# STM32H503xx register map
File version: 1.0
Registers are 32-bit, read-write, reset 0x0 unless marked. A register's access mark holds for its fields unless they carry their own. Offsets are from the block's base; [hi:lo] are bit positions; {n}, {i} and the like mark numbered series; 'fields as' and 'values as' point back to an identical list.

## USB_DRD_PMA_BUFF — Universal Serial Bus PacketMemoryArea Buffer Descriptor Table
Base 0x40016400
0x00 TXBD — Transmission buffer address
0x04 RXBD — Reception buffer address

## CRC — CRC calculation unit
Base 0x40023000
0x00 DR — CRC Data register
  [31:0] DR — Data register bits
0x04 IDR — CRC Independent data register
  [31:0] IDR — General-purpose 32-bits data register bits
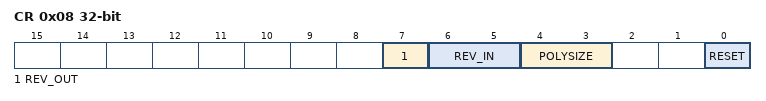
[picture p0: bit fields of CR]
0x08 CR — CRC Control register
  [7] REV_OUT — REV_OUT Reverse Output Data bits
    0=NONE (Output Data bit order not affected); 1=BIT (Output Data bit reversal done by bit)
  [6:5] REV_IN — REV_IN Reverse Input Data bits
    0=NONE (Input Data bit order not affected); 1=BYTE (Definition for compatibility with legacy code); 2=HALFWORD (Definition for compatibility with legacy code); 3=WORD (Definition for compatibility with legacy code)
  [4:3] POLYSIZE — Polynomial size bits
    0=POLYLENGTH_32B (32 bits Polynomial size); 1=POLYLENGTH_16B (16 bits Polynomial size); 2=POLYLENGTH_8B (8 bits Polynomial size); 3=POLYLENGTH_7B (7 bits Polynomial size)
  [0] RESET — RESET the CRC computation unit bit
0x10 INIT — Initial CRC value register
  [31:0] INIT — Initial CRC value bits
0x14 POL — CRC polynomial register
  [31:0] POL — Coefficients of the polynomial

## RAMCFG
Base 0x40026000
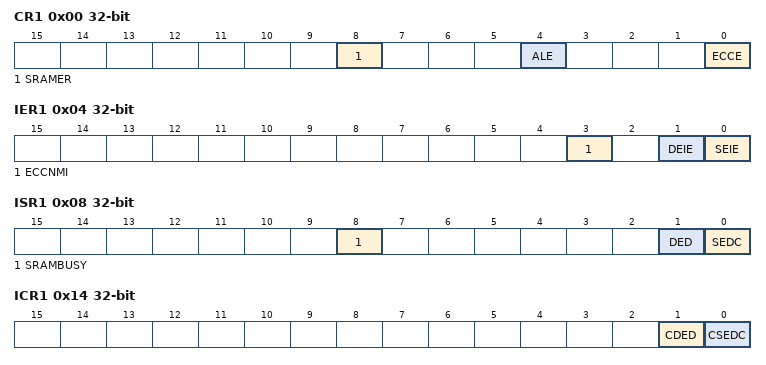
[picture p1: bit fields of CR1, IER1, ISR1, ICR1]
0x00 CR1 — Control Register
  [8] SRAMER — Start Erase
  [4] ALE — Address Latching Enable
  [0] ECCE — ECC Enable
0x04 IER1 — Interrupt Enable Register
  [3] ECCNMI — NMI redirection interrupt
  [1] DEIE — Double Error Interrupt Enable
  [0] SEIE — Single Error Interrupt Enable
0x08 ISR1 — Interrupt Status Register
  [8] SRAMBUSY — SRAM busy flag
  [1] DED — Double Error Detected flag
  [0] SEDC — Single Error Detected and Corrected flag
0x0C SEAR1 — ECC Single Error Address Register
  [31:0] ESEA — ECC Single Error Address
0x10 DEAR1 — ECC Double Error Address Register
  [31:0] EDEA — ECC Double Error Address
0x14 ICR1 — Interrupt Clear Register
  [1] CDED — Clear ECC Double Error Detected Flag
  [0] CSEDC — Clear ECC Single Error Detected and Corrected Flag
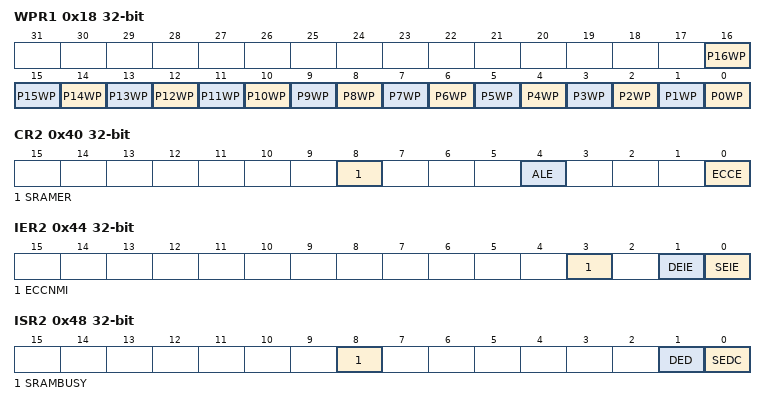
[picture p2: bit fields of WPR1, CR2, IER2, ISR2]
0x18 WPR1 — SRAM Write Protection Register 1
  [n] P{n}WP (n=0..16) — Write Protection Page {n:02}
0x1C WPR21 — SRAM Write Protection Register 2
0x24 ECCKEY1 — SRAM ECC Key Register
0x28 ERKEYR1 — SRAM Erase Key Register
  [7:0] ERASEKEY — Erase Write Protection Key
0x40 CR2 — Control Register
  fields as CR1
0x44 IER2 — Interrupt Enable Register
  fields as IER1
0x48 ISR2 — Interrupt Status Register
  fields as ISR1
0x4C SEAR2 — ECC Single Error Address Register
  [31:0] ESEA — ECC Single Error Address
0x50 DEAR2 — ECC Double Error Address Register
  [31:0] EDEA — ECC Double Error Address
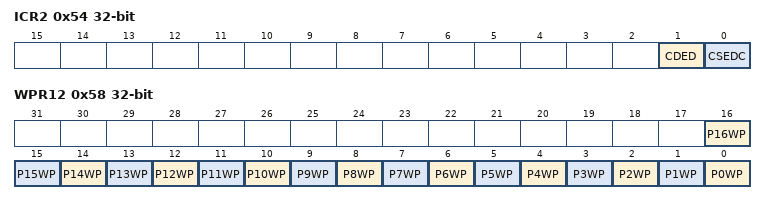
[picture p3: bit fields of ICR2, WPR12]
0x54 ICR2 — Interrupt Clear Register
  fields as ICR1
0x58 WPR12 — SRAM Write Protection Register 1
  [n] P{n}WP (n=0..16) — Write Protection Page {n:02}
0x5C WPR2 — SRAM Write Protection Register 2
0x64 ECCKEY2 — SRAM ECC Key Register
0x68 ERKEYR2 — SRAM Erase Key Register
  [7:0] ERASEKEY — Erase Write Protection Key

## RAMCFG_BKPRAM — SRAMs configuration controller
Base 0x40026100
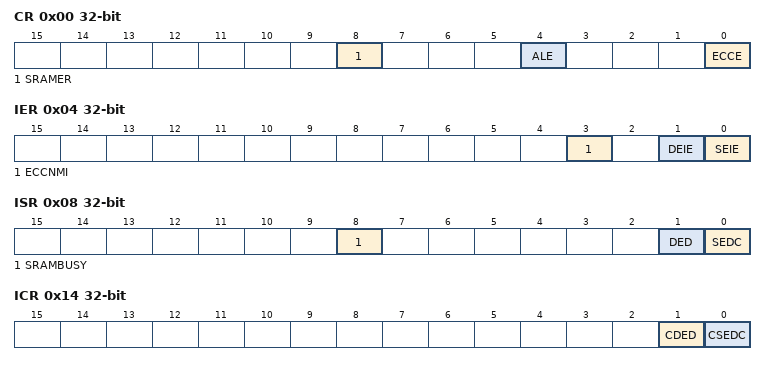
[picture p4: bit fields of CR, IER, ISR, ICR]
0x00 CR — Control Register
  [8] SRAMER — Start Erase
  [4] ALE — Address Latching Enable
  [0] ECCE — ECC Enable
0x04 IER — Interrupt Enable Register
  [3] ECCNMI — NMI redirection interrupt
  [1] DEIE — Double Error Interrupt Enable
  [0] SEIE — Single Error Interrupt Enable
0x08 ISR — Interrupt Status Register
  [8] SRAMBUSY — SRAM busy flag
  [1] DED — Double Error Detected flag
  [0] SEDC — Single Error Detected and Corrected flag
0x0C SEAR — ECC Single Error Address Register
  [31:0] ESEA — ECC Single Error Address
0x10 DEAR — ECC Double Error Address Register
  [31:0] EDEA — ECC Double Error Address
0x14 ICR — Interrupt Clear Register
  [1] CDED — Clear ECC Double Error Detected Flag
  [0] CSEDC — Clear ECC Single Error Detected and Corrected Flag
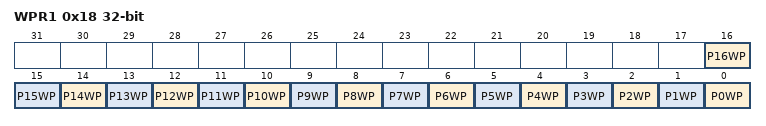
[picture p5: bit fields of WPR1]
0x18 WPR1 — SRAM Write Protection Register 1
  [n] P{n}WP (n=0..16) — Write Protection Page {n:02}
0x1C WPR2 — SRAM Write Protection Register 2
0x24 ECCKEY — SRAM ECC Key Register
0x28 ERKEYR — SRAM Erase Key Register
  [7:0] ERASEKEY — Erase Write Protection Key
